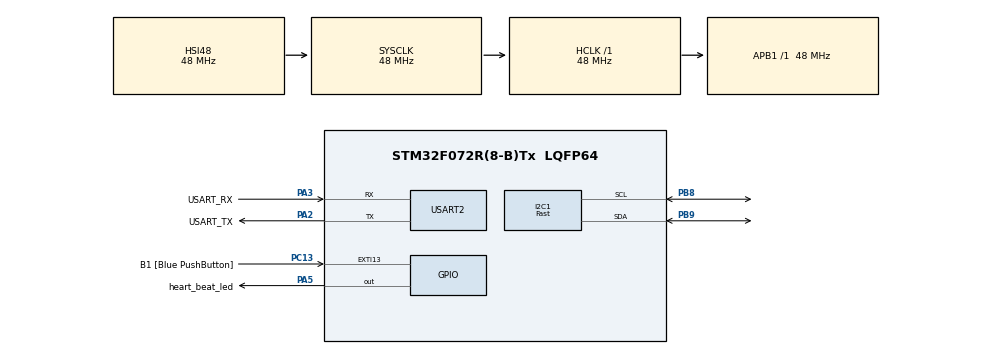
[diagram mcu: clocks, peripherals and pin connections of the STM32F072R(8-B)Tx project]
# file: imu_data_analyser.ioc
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FREERTOS.Tasks01=defaultTask,24,128,StartDefaultTask,Default,NULL,Dynamic,NULL,NULL
I2C1.I2C_Speed_Mode=I2C_Fast
I2C1.Timing=0x0010020A
Mcu.Family=STM32F0
Mcu.Name=STM32F072R(8-B)Tx
Mcu.Package=LQFP64
NVIC.TIM7_IRQn=true\:3\:0\:false\:false\:true\:false\:false\:true\:true
NVIC.TimeBase=TIM7_IRQn
NVIC.TimeBaseIP=TIM7
PA13.GPIO_Label=TMS
PA13.Mode=Serial_Wire
PA13.Signal=SYS_SWDIO
PA14.GPIO_Label=TCK
PA14.Mode=Serial_Wire
PA14.Signal=SYS_SWCLK
PA2.GPIO_Label=USART_TX
PA2.GPIO_Mode=GPIO_MODE_AF_PP
PA2.GPIO_PuPd=GPIO_NOPULL
PA2.GPIO_Speed=GPIO_SPEED_FREQ_HIGH
PA2.Mode=Asynchronous
PA2.Signal=USART2_TX
PA3.GPIO_Label=USART_RX
PA3.GPIO_Mode=GPIO_MODE_AF_PP
PA3.GPIO_PuPd=GPIO_NOPULL
PA3.GPIO_Speed=GPIO_SPEED_FREQ_HIGH
PA3.Mode=Asynchronous
PA3.Signal=USART2_RX
PA5.GPIO_Label=heart_beat_led
PA5.GPIO_Mode=GPIO_MODE_OUTPUT_PP
PA5.GPIO_PuPd=GPIO_NOPULL
PA5.GPIO_Speed=GPIO_SPEED_FREQ_LOW
PA5.Signal=GPIO_Output
PB8.GPIO_Pu=GPIO_PULLUP
PB8.Mode=I2C
PB8.Signal=I2C1_SCL
PB9.GPIO_Pu=GPIO_PULLUP
PB9.Mode=I2C
PB9.Signal=I2C1_SDA
PC13.GPIO_Label=B1 [Blue PushButton]
PC13.GPIO_ModeDefaultEXTI=GPIO_MODE_IT_FALLING
PC13.Signal=GPXTI13
PC14-OSC32_IN.Mode=LSE-External-Oscillator
PC14-OSC32_IN.Signal=RCC_OSC32_IN
PC15-OSC32_OUT.Mode=LSE-External-Oscillator
PC15-OSC32_OUT.Signal=RCC_OSC32_OUT
PF0-OSC_IN.Mode=HSE-External-Clock-Source
PF0-OSC_IN.Signal=RCC_OSC_IN
PF1-OSC_OUT.Signal=RCC_OSC_OUT
ProjectManager.HeapSize=0x200
ProjectManager.StackSize=0x400
ProjectManager.TargetToolchain=STM32CubeIDE
RCC.AHBFreq_Value=48000000
RCC.APB1Freq_Value=48000000
RCC.APB1TimFreq_Value=48000000
RCC.FLatency-AdvancedSettings=FLASH_LATENCY_1
RCC.HCLKFreq_Value=48000000
RCC.PLLDivider=RCC_PREDIV_DIV2
RCC.PLLMUL=RCC_PLL_MUL12
RCC.PREFETCH_ENABLE-AdvancedSettings=1
RCC.SYSCLKFreq_VALUE=48000000
RCC.SYSCLKSource=RCC_SYSCLKSOURCE_HSI48
USART2.VirtualMode=VM_ASYNC
USART2.VirtualMode-Asynchronous=VM_ASYNC
VP_FREERTOS_VS_CMSIS_V2.Mode=CMSIS_V2
VP_SYS_VS_tim7.Mode=TIM7
board=NUCLEO-F072RB

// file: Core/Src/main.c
/* USER CODE BEGIN Header */
/**
  ******************************************************************************
  * @file           : main.c
  * @brief          : Main program body
  ******************************************************************************
  * @attention
  *
  * Copyright (c) 2024 STMicroelectronics.
  * All rights reserved.
  *
  * This software is licensed under terms that can be found in the LICENSE file
  * in the root directory of this software component.
  * If no LICENSE file comes with this software, it is provided AS-IS.
  *
  ******************************************************************************
  */
/* USER CODE END Header */
#include <core_library/debug_log/debug_log.h>
#include "main.h"
#include "cmsis_os.h"

/* USER CODE BEGIN Includes */
#include "debug_log/debug_log.h"
#include "i2c/i2c_helper.h"
#include "data_processing_th/data_processing_th.h"
#include "data_acquisition/data_acquisition_th.h"

/* USER CODE END Includes */

I2C_HandleTypeDef hi2c1;

UART_HandleTypeDef huart2;

/* Definitions for defaultTask */
osThreadId_t defaultTaskHandle;
const osThreadAttr_t defaultTask_attributes = {
  .name = "defaultTask",
  .stack_size = 128 * 4,
  .priority = (osPriority_t) osPriorityNormal,
};

void SystemClock_Config(void);
static void MX_GPIO_Init(void);
static void MX_USART2_UART_Init(void);
static void MX_I2C1_Init(void);
void StartDefaultTask(void *argument);

int main(void)
{

  /* MCU Configuration--------------------------------------------------------*/

  /* Reset of all peripherals, Initializes the Flash interface and the Systick. */
  HAL_Init();

  /* Configure the system clock */
  SystemClock_Config();

  /* Initialize all configured peripherals */
  MX_GPIO_Init();
  MX_USART2_UART_Init();
  MX_I2C1_Init();
  /* USER CODE BEGIN 2 */
  debug_log_init(&huart2, LOG_LEVEL_INFO);
  data_aquisition_int(&hi2c1);
  data_processing_init();

  /* USER CODE END 2 */

  /* Init scheduler */
  osKernelInitialize();

  /* Create the thread(s) */
  /* creation of defaultTask */
  defaultTaskHandle = osThreadNew(StartDefaultTask, NULL, &defaultTask_attributes);

  /* USER CODE BEGIN RTOS_THREADS */
  /* add threads, ... */
  dataProcessingTaskHandle = osThreadNew(data_processing, NULL, &dataProcessingTaskAttributes);
  dataAquisitionTaskHandle = osThreadNew(data_aquisition, NULL, &dataAquisitionTaskAttributes);

  /* USER CODE END RTOS_THREADS */

  /* Start scheduler */
  osKernelStart();

  /* We should never get here as control is now taken by the scheduler */

  /* Infinite loop */
  while (1)
  {

  }
}

void SystemClock_Config(void)
{
  RCC_OscInitTypeDef RCC_OscInitStruct = {0};
  RCC_ClkInitTypeDef RCC_ClkInitStruct = {0};
  RCC_PeriphCLKInitTypeDef PeriphClkInit = {0};

  /** Initializes the RCC Oscillators according to the specified parameters
  * in the RCC_OscInitTypeDef structure.
  */
  RCC_OscInitStruct.OscillatorType = RCC_OSCILLATORTYPE_HSI|RCC_OSCILLATORTYPE_HSI48;
  RCC_OscInitStruct.HSIState = RCC_HSI_ON;
  RCC_OscInitStruct.HSI48State = RCC_HSI48_ON;
  RCC_OscInitStruct.HSICalibrationValue = RCC_HSICALIBRATION_DEFAULT;
  RCC_OscInitStruct.PLL.PLLState = RCC_PLL_NONE;
  if (HAL_RCC_OscConfig(&RCC_OscInitStruct) != HAL_OK)
  {
    Error_Handler();
  }

  /** Initializes the CPU, AHB and APB buses clocks
  */
  RCC_ClkInitStruct.ClockType = RCC_CLOCKTYPE_HCLK|RCC_CLOCKTYPE_SYSCLK
                              |RCC_CLOCKTYPE_PCLK1;
  RCC_ClkInitStruct.SYSCLKSource = RCC_SYSCLKSOURCE_HSI48;
  RCC_ClkInitStruct.AHBCLKDivider = RCC_SYSCLK_DIV1;
  RCC_ClkInitStruct.APB1CLKDivider = RCC_HCLK_DIV1;

  if (HAL_RCC_ClockConfig(&RCC_ClkInitStruct, FLASH_LATENCY_1) != HAL_OK)
  {
    Error_Handler();
  }
  PeriphClkInit.PeriphClockSelection = RCC_PERIPHCLK_USART2|RCC_PERIPHCLK_I2C1;
  PeriphClkInit.Usart2ClockSelection = RCC_USART2CLKSOURCE_PCLK1;
  PeriphClkInit.I2c1ClockSelection = RCC_I2C1CLKSOURCE_HSI;
  if (HAL_RCCEx_PeriphCLKConfig(&PeriphClkInit) != HAL_OK)
  {
    Error_Handler();
  }
}

static void MX_I2C1_Init(void)
{

  hi2c1.Instance = I2C1;
  hi2c1.Init.Timing = 0x0010020A;
  hi2c1.Init.OwnAddress1 = 0;
  hi2c1.Init.AddressingMode = I2C_ADDRESSINGMODE_7BIT;
  hi2c1.Init.DualAddressMode = I2C_DUALADDRESS_DISABLE;
  hi2c1.Init.OwnAddress2 = 0;
  hi2c1.Init.OwnAddress2Masks = I2C_OA2_NOMASK;
  hi2c1.Init.GeneralCallMode = I2C_GENERALCALL_DISABLE;
  hi2c1.Init.NoStretchMode = I2C_NOSTRETCH_DISABLE;
  if (HAL_I2C_Init(&hi2c1) != HAL_OK)
  {
    Error_Handler();
  }

  /** Configure Analogue filter
  */
  if (HAL_I2CEx_ConfigAnalogFilter(&hi2c1, I2C_ANALOGFILTER_ENABLE) != HAL_OK)
  {
    Error_Handler();
  }

  /** Configure Digital filter
  */
  if (HAL_I2CEx_ConfigDigitalFilter(&hi2c1, 0) != HAL_OK)
  {
    Error_Handler();
  }

}

static void MX_USART2_UART_Init(void)
{

  huart2.Instance = USART2;
  huart2.Init.BaudRate = 38400;
  huart2.Init.WordLength = UART_WORDLENGTH_8B;
  huart2.Init.StopBits = UART_STOPBITS_1;
  huart2.Init.Parity = UART_PARITY_NONE;
  huart2.Init.Mode = UART_MODE_TX_RX;
  huart2.Init.HwFlowCtl = UART_HWCONTROL_NONE;
  huart2.Init.OverSampling = UART_OVERSAMPLING_16;
  huart2.Init.OneBitSampling = UART_ONE_BIT_SAMPLE_DISABLE;
  huart2.AdvancedInit.AdvFeatureInit = UART_ADVFEATURE_NO_INIT;
  if (HAL_UART_Init(&huart2) != HAL_OK)
  {
    Error_Handler();
  }

}

static void MX_GPIO_Init(void)
{
  GPIO_InitTypeDef GPIO_InitStruct = {0};

  /* GPIO Ports Clock Enable */
  __HAL_RCC_GPIOC_CLK_ENABLE();
  __HAL_RCC_GPIOF_CLK_ENABLE();
  __HAL_RCC_GPIOA_CLK_ENABLE();
  __HAL_RCC_GPIOB_CLK_ENABLE();

  /*Configure GPIO pin Output Level */
  HAL_GPIO_WritePin(heart_beat_led_GPIO_Port, heart_beat_led_Pin, GPIO_PIN_RESET);

  /*Configure GPIO pin : B1_Pin */
  GPIO_InitStruct.Pin = B1_Pin;
  GPIO_InitStruct.Mode = GPIO_MODE_IT_FALLING;
  GPIO_InitStruct.Pull = GPIO_NOPULL;
  HAL_GPIO_Init(B1_GPIO_Port, &GPIO_InitStruct);

  /*Configure GPIO pin : heart_beat_led_Pin */
  GPIO_InitStruct.Pin = heart_beat_led_Pin;
  GPIO_InitStruct.Mode = GPIO_MODE_OUTPUT_PP;
  GPIO_InitStruct.Pull = GPIO_NOPULL;
  GPIO_InitStruct.Speed = GPIO_SPEED_FREQ_LOW;
  HAL_GPIO_Init(heart_beat_led_GPIO_Port, &GPIO_InitStruct);

}

void StartDefaultTask(void *argument)
{
  for(;;)
  {
    osDelay(1);
  }
}

void HAL_TIM_PeriodElapsedCallback(TIM_HandleTypeDef *htim)
{
  if (htim->Instance == TIM7) {
    HAL_IncTick();
  }
}

void Error_Handler(void)
{
  __disable_irq();
  while (1)
  {
  }
}
